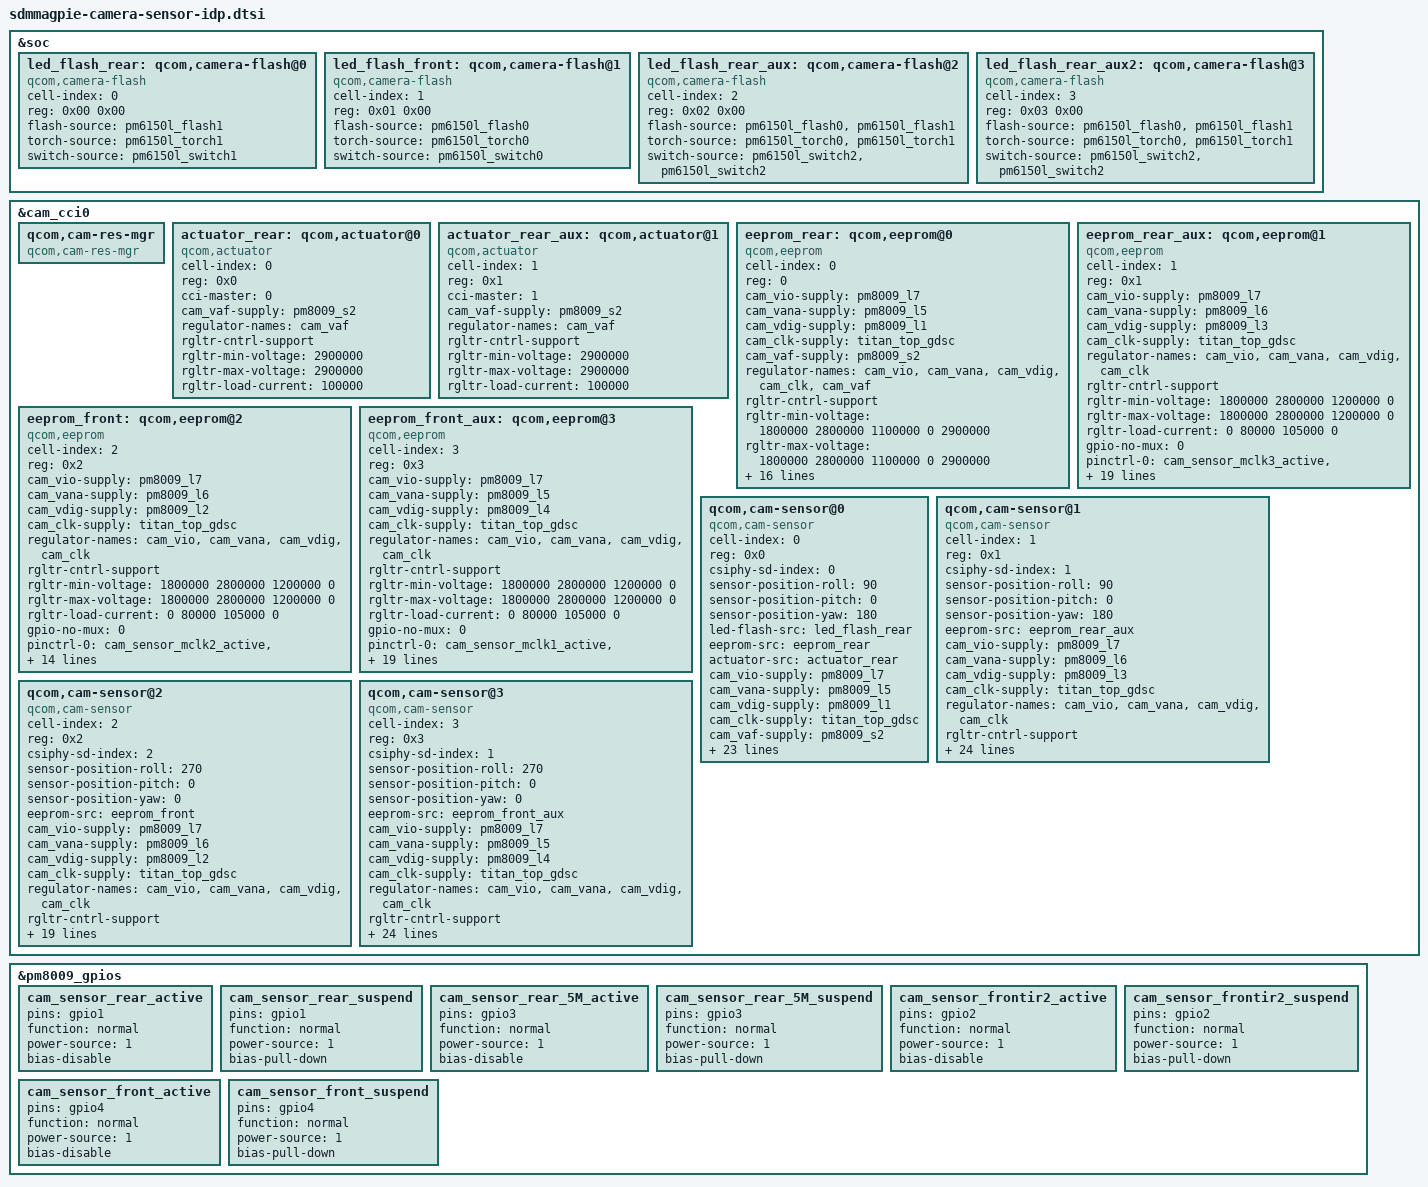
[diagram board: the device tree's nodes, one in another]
/*
 * Copyright (c) 2018-2019, The Linux Foundation. All rights reserved.
 *
 * This program is free software; you can redistribute it and/or modify
 * it under the terms of the GNU General Public License version 2 and
 * only version 2 as published by the Free Software Foundation.
 *
 * This program is distributed in the hope that it will be useful,
 * but WITHOUT ANY WARRANTY; without even the implied warranty of
 * MERCHANTABILITY or FITNESS FOR A PARTICULAR PURPOSE.  See the
 * GNU General Public License for more details.
 */

#include <dt-bindings/clock/qcom,camcc-sdmmagpie.h>

&soc {
	led_flash_rear: qcom,camera-flash@0 {
		cell-index = <0>;
		reg = <0x00 0x00>;
		compatible = "qcom,camera-flash";
		flash-source = <&pm6150l_flash1>;
		torch-source = <&pm6150l_torch1>;
		switch-source = <&pm6150l_switch1>;
		status = "ok";
	};

	led_flash_front: qcom,camera-flash@1 {
		cell-index = <1>;
		reg = <0x01 0x00>;
		compatible = "qcom,camera-flash";
		flash-source = <&pm6150l_flash0>;
		torch-source = <&pm6150l_torch0>;
		switch-source = <&pm6150l_switch0>;
		status = "ok";
	};

	led_flash_rear_aux: qcom,camera-flash@2 {
		cell-index = <2>;
		reg = <0x02 0x00>;
		compatible = "qcom,camera-flash";
		flash-source = <&pm6150l_flash0 &pm6150l_flash1>;
		torch-source = <&pm6150l_torch0 &pm6150l_torch1>;
		switch-source = <&pm6150l_switch2 &pm6150l_switch2>;
		status = "ok";
	};

	led_flash_rear_aux2: qcom,camera-flash@3 {
		cell-index = <3>;
		reg = <0x03 0x00>;
		compatible = "qcom,camera-flash";
		flash-source = <&pm6150l_flash0 &pm6150l_flash1>;
		torch-source = <&pm6150l_torch0 &pm6150l_torch1>;
		switch-source = <&pm6150l_switch2 &pm6150l_switch2>;
		status = "ok";
	};
};

&cam_cci0 {
	qcom,cam-res-mgr {
		compatible = "qcom,cam-res-mgr";
		status = "ok";
	};

	actuator_rear: qcom,actuator@0 {
		cell-index = <0>;
		reg = <0x0>;
		compatible = "qcom,actuator";
		cci-master = <0>;
		cam_vaf-supply = <&pm8009_s2>;
		regulator-names = "cam_vaf";
		rgltr-cntrl-support;
		rgltr-min-voltage = <2900000>;
		rgltr-max-voltage = <2900000>;
		rgltr-load-current = <100000>;
	};

	actuator_rear_aux: qcom,actuator@1 {
		cell-index = <1>;
		reg = <0x1>;
		compatible = "qcom,actuator";
		cci-master = <1>;
		cam_vaf-supply = <&pm8009_s2>;
		regulator-names = "cam_vaf";
		rgltr-cntrl-support;
		rgltr-min-voltage = <2900000>;
		rgltr-max-voltage = <2900000>;
		rgltr-load-current = <100000>;
	};

	eeprom_rear: qcom,eeprom@0 {
		cell-index = <0>;
		reg = <0>;
		compatible = "qcom,eeprom";
		cam_vio-supply = <&pm8009_l7>;
		cam_vana-supply = <&pm8009_l5>;
		cam_vdig-supply = <&pm8009_l1>;
		cam_clk-supply = <&titan_top_gdsc>;
		cam_vaf-supply = <&pm8009_s2>;
		regulator-names = "cam_vio", "cam_vana", "cam_vdig",
			"cam_clk", "cam_vaf";
		rgltr-cntrl-support;
		rgltr-min-voltage = <1800000 2800000 1100000 0 2900000>;
		rgltr-max-voltage = <1800000 2800000 1100000 0 2900000>;
		rgltr-load-current = <0 80000 105000 0 100000>;
		gpio-no-mux = <0>;
		pinctrl-names = "cam_default", "cam_suspend";
		pinctrl-0 = <&cam_sensor_mclk0_active
				&cam_sensor_rear_active>;
		pinctrl-1 = <&cam_sensor_mclk0_suspend
				&cam_sensor_rear_suspend>;
		gpios = <&tlmm 13 0>,
			<&pm8009_gpios 1 0>;
		gpio-reset = <1>;
		gpio-req-tbl-num = <0 1>;
		gpio-req-tbl-flags = <1 0>;
		gpio-req-tbl-label = "CAMIF_MCLK0",
					"CAM_RESET0";
		sensor-mode = <0>;
		cci-master = <0>;
		status = "ok";
		clocks = <&clock_camcc CAM_CC_MCLK0_CLK>;
		clock-names = "cam_clk";
		clock-cntl-level = "turbo";
		clock-rates = <24000000>;
	};

	eeprom_rear_aux: qcom,eeprom@1 {
		cell-index = <1>;
		reg = <0x1>;
		compatible = "qcom,eeprom";
		cam_vio-supply = <&pm8009_l7>;
		cam_vana-supply = <&pm8009_l6>;
		cam_vdig-supply = <&pm8009_l3>;
		cam_clk-supply = <&titan_top_gdsc>;
		regulator-names = "cam_vio", "cam_vana", "cam_vdig",
			"cam_clk";
		rgltr-cntrl-support;
		rgltr-min-voltage = <1800000 2800000 1200000 0>;
		rgltr-max-voltage = <1800000 2800000 1200000 0>;
		rgltr-load-current = <0 80000 105000 0>;
		gpio-no-mux = <0>;
		pinctrl-names = "cam_default", "cam_suspend";
		pinctrl-0 = <&cam_sensor_mclk3_active &cam_sensor_5M_rear1_active
				&cam_sensor_rear_5M_active>;
		pinctrl-1 = <&cam_sensor_mclk3_suspend &cam_sensor_5M_rear1_suspend
				&cam_sensor_rear_5M_suspend>;
		gpios = <&tlmm 16 0>,  //clk
                        <&tlmm 95 0>,//need high custom1
                        <&tlmm 71 0>,//need low custom2
			<&pm8009_gpios 3 0>;
                gpio-custom1 = <1>;
                gpio-custom2 = <2>;
		gpio-reset = <3>;
		gpio-req-tbl-num = <0 1 2 3>;
		gpio-req-tbl-flags = <1 0 0 0>;
		gpio-req-tbl-label = "CAMIF_MCLK3","CAM_CUSTOM1","CAM_CUSTOM2","CAM_RESET3";
		sensor-mode = <0>;
		cci-master = <1>;
		status = "ok";
		clocks = <&clock_camcc CAM_CC_MCLK3_CLK>;
		clock-names = "cam_clk";
		clock-cntl-level = "turbo";
		clock-rates = <24000000>;
	};

	eeprom_front: qcom,eeprom@2 {
		cell-index = <2>;
		reg = <0x2>;
		compatible = "qcom,eeprom";
		cam_vio-supply = <&pm8009_l7>;
		cam_vana-supply = <&pm8009_l6>;
		cam_vdig-supply = <&pm8009_l2>;
		cam_clk-supply = <&titan_top_gdsc>;
		regulator-names = "cam_vio", "cam_vana", "cam_vdig",
			"cam_clk";
		rgltr-cntrl-support;
		rgltr-min-voltage = <1800000 2800000 1200000 0>;
		rgltr-max-voltage = <1800000 2800000 1200000 0>;
		rgltr-load-current = <0 80000 105000 0>;
		gpio-no-mux = <0>;
		pinctrl-names = "cam_default", "cam_suspend";
		pinctrl-0 = <&cam_sensor_mclk2_active
				 &cam_sensor_front_active>;
		pinctrl-1 = <&cam_sensor_mclk2_suspend
				 &cam_sensor_front_suspend>;
		gpios = <&tlmm 15 0>,
			<&pm8009_gpios 4 0>;
		gpio-reset = <1>;
		gpio-req-tbl-num = <0 1>;
		gpio-req-tbl-flags = <1 0>;
		gpio-req-tbl-label = "CAMIF_MCLK2",
					"CAM_RESET2";
		sensor-mode = <0>;
		cci-device = <1>;
		cci-master = <0>;
		status = "ok";
		clocks = <&clock_camcc CAM_CC_MCLK2_CLK>;
		clock-names = "cam_clk";
		clock-cntl-level = "turbo";
		clock-rates = <24000000>;
	};

	eeprom_front_aux: qcom,eeprom@3 {
		cell-index = <3>;
		reg = <0x3>;
		compatible = "qcom,eeprom";
		cam_vio-supply = <&pm8009_l7>;
		cam_vana-supply = <&pm8009_l5>;
		cam_vdig-supply = <&pm8009_l4>;
		cam_clk-supply = <&titan_top_gdsc>;
		regulator-names = "cam_vio", "cam_vana", "cam_vdig",
			"cam_clk";
		rgltr-cntrl-support;
		rgltr-min-voltage = <1800000 2800000 1200000 0>;
		rgltr-max-voltage = <1800000 2800000 1200000 0>;
		rgltr-load-current = <0 80000 105000 0>;
		gpio-no-mux = <0>;
		pinctrl-names = "cam_default", "cam_suspend";
                pinctrl-0 = <&cam_sensor_mclk1_active
                                &cam_sensor_frontir_active
                                &cam_sensor_frontir2_active>;
                pinctrl-1 = <&cam_sensor_mclk1_suspend
                                &cam_sensor_frontir_suspend
                                &cam_sensor_frontir2_suspend>;

		gpios = <&tlmm 14 0>,  //clk
                        <&tlmm 95 0>,//sw_sel low custom1
                        <&tlmm 71 0>,//sw_en low custom2
			<&pm8009_gpios 2 0>;
                gpio-custom1 = <1>;
                gpio-custom2 = <2>;
		gpio-reset = <3>;
		gpio-req-tbl-num = <0 1 2 3>;
		gpio-req-tbl-flags = <1 0 0 0>;
		gpio-req-tbl-label = "CAMIF_MCLK1","CAM_CUSTOM1","CAM_CUSTOM2","CAM_RESET1";
		sensor-mode = <0>;
		cci-master = <1>;
		status = "ok";
		clocks = <&clock_camcc CAM_CC_MCLK1_CLK>;
		clock-names = "cam_clk";
		clock-cntl-level = "turbo";
		clock-rates = <24000000>;
	};

	qcom,cam-sensor@0 {
		cell-index = <0>;
		compatible = "qcom,cam-sensor";
		reg = <0x0>;
		csiphy-sd-index = <0>;
		sensor-position-roll = <90>;
		sensor-position-pitch = <0>;
		sensor-position-yaw = <180>;
		led-flash-src = <&led_flash_rear>;
		eeprom-src = <&eeprom_rear>;
		actuator-src = <&actuator_rear>;
		cam_vio-supply = <&pm8009_l7>;
		cam_vana-supply = <&pm8009_l5>;
		cam_vdig-supply = <&pm8009_l1>;
		cam_clk-supply = <&titan_top_gdsc>;
		cam_vaf-supply = <&pm8009_s2>;
		regulator-names = "cam_vio", "cam_vana", "cam_vdig",
			"cam_clk","cam_vaf";
		rgltr-cntrl-support;
		rgltr-min-voltage = <1800000 2800000 1100000 0 2900000>;
		rgltr-max-voltage = <1800000 2800000 1100000 0 2900000>;
		rgltr-load-current = <0 80000 105000 0 100000>;
		gpio-no-mux = <0>;
		pinctrl-names = "cam_default", "cam_suspend";
		pinctrl-0 = <&cam_sensor_mclk0_active
				&cam_sensor_rear_active>;
		pinctrl-1 = <&cam_sensor_mclk0_suspend
				&cam_sensor_rear_suspend>;
		gpios = <&tlmm 13 0>,
			<&pm8009_gpios 1 0>;
		gpio-reset = <1>;
		gpio-req-tbl-num = <0 1>;
		gpio-req-tbl-flags = <1 0>;
		gpio-req-tbl-label = "CAMIF_MCLK0",
					"CAM_RESET0";
		sensor-mode = <0>;
		cci-master = <0>;
		status = "ok";
		clocks = <&clock_camcc CAM_CC_MCLK0_CLK>;
		clock-names = "cam_clk";
		clock-cntl-level = "turbo";
		clock-rates = <24000000>;
	};

	qcom,cam-sensor@1 {
		cell-index = <1>;
		compatible = "qcom,cam-sensor";
		reg = <0x1>;
		csiphy-sd-index = <1>;
		sensor-position-roll = <90>;
		sensor-position-pitch = <0>;
		sensor-position-yaw = <180>;
		//led-flash-src = <&led_flash_rear_aux>;
		eeprom-src = <&eeprom_rear_aux>;
		//actuator-src = <&actuator_rear_aux>;
		cam_vio-supply = <&pm8009_l7>;
		cam_vana-supply = <&pm8009_l6>;
		cam_vdig-supply = <&pm8009_l3>;
		cam_clk-supply = <&titan_top_gdsc>;
		regulator-names = "cam_vio", "cam_vana", "cam_vdig",
			"cam_clk";
		rgltr-cntrl-support;
		rgltr-min-voltage = <1800000 2800000 1200000 0>;
		rgltr-max-voltage = <1800000 2800000 1200000 0>;
		rgltr-load-current = <0 80000 105000 0>;
		gpio-no-mux = <0>;
		pinctrl-names = "cam_default", "cam_suspend";
		pinctrl-0 = <&cam_sensor_mclk3_active &cam_sensor_5M_rear1_active
				&cam_sensor_rear_5M_active>;
		pinctrl-1 = <&cam_sensor_mclk3_suspend &cam_sensor_5M_rear1_suspend
				&cam_sensor_rear_5M_suspend>;
		gpios = <&tlmm 16 0>,  //clk
                        <&tlmm 95 0>,//need high custom1
                        <&tlmm 71 0>,//need low custom2
			<&pm8009_gpios 3 0>;
                
                gpio-custom1 = <1>;
                gpio-custom2 = <2>;
		gpio-reset = <3>;
		gpio-req-tbl-num = <0 1 2 3>;
		gpio-req-tbl-flags = <1 0 0 0>;
		gpio-req-tbl-label = "CAMIF_MCLK3","CAM_CUSTOM1","CAM_CUSTOM2","CAM_RESET3";
		sensor-mode = <0>;
		cci-master = <1>;
		status = "ok";
		clocks = <&clock_camcc CAM_CC_MCLK3_CLK>;
		clock-names = "cam_clk";
		clock-cntl-level = "turbo";
		clock-rates = <24000000>;
	};

	qcom,cam-sensor@2 {//front rgb
		cell-index = <2>;
		compatible = "qcom,cam-sensor";
		reg = <0x2>;
		csiphy-sd-index = <2>;
		sensor-position-roll = <270>;
		sensor-position-pitch = <0>;
		sensor-position-yaw = <0>;
		eeprom-src = <&eeprom_front>;
		cam_vio-supply = <&pm8009_l7>;
		cam_vana-supply = <&pm8009_l6>;
		cam_vdig-supply = <&pm8009_l2>;
		cam_clk-supply = <&titan_top_gdsc>;
		regulator-names = "cam_vio", "cam_vana", "cam_vdig",
			"cam_clk";
		rgltr-cntrl-support;
		rgltr-min-voltage = <1800000 2800000 1200000 0>;
		rgltr-max-voltage = <1800000 2800000 1200000 0>;
		rgltr-load-current = <0 80000 105000 0>;
		gpio-no-mux = <0>;
		pinctrl-names = "cam_default", "cam_suspend";
		pinctrl-0 = <&cam_sensor_mclk2_active
				 &cam_sensor_front_active>;
		pinctrl-1 = <&cam_sensor_mclk2_suspend
				 &cam_sensor_front_suspend>;
		gpios = <&tlmm 15 0>,
			<&pm8009_gpios 4 0>;
		gpio-reset = <1>;
		gpio-req-tbl-num = <0 1>;
		gpio-req-tbl-flags = <1 0>;
		gpio-req-tbl-label = "CAMIF_MCLK2",
					"CAM_RESET2";
		sensor-mode = <0>;
		cci-device = <1>;
		cci-master = <0>;
		status = "ok";
		clocks = <&clock_camcc CAM_CC_MCLK2_CLK>;
		clock-names = "cam_clk";
		clock-cntl-level = "turbo";
		clock-rates = <24000000>;
	};

	qcom,cam-sensor@3 {//front IR
		cell-index = <3>;
		compatible = "qcom,cam-sensor";
		reg = <0x3>;
		csiphy-sd-index = <1>;
		sensor-position-roll = <270>;
		sensor-position-pitch = <0>;
		sensor-position-yaw = <0>;
                //led-flash-src = <&led_flash_front>;
		eeprom-src = <&eeprom_front_aux>;
		cam_vio-supply = <&pm8009_l7>;
		cam_vana-supply = <&pm8009_l5>;
		cam_vdig-supply = <&pm8009_l4>;
		cam_clk-supply = <&titan_top_gdsc>;
		regulator-names = "cam_vio", "cam_vana", "cam_vdig",
				"cam_clk";
		rgltr-cntrl-support;
		rgltr-min-voltage = <1800000 2800000 1200000 0>;
		rgltr-max-voltage = <1800000 2800000 1200000 0>;
		rgltr-load-current = <0 80000 105000 0>;
		gpio-no-mux = <0>;
		pinctrl-names = "cam_default", "cam_suspend";
		pinctrl-0 = <&cam_sensor_mclk1_active
                                &cam_sensor_frontir_active
				&cam_sensor_frontir2_active>;
		pinctrl-1 = <&cam_sensor_mclk1_suspend
                                &cam_sensor_frontir_suspend
				&cam_sensor_frontir2_suspend>;
                gpios = <&tlmm 14 0>,
                      <&tlmm 95 0>,//sw_sel low custom1
                      <&tlmm 71 0>,//sw_en low custom2
                      <&pm8009_gpios 2 0>;
                gpio-custom1 = <1>;
                gpio-custom2 = <2>;
		gpio-reset = <3>;
		gpio-req-tbl-num = <0 1 2 3>;
		gpio-req-tbl-flags = <1 0 0 0>;
		gpio-req-tbl-label = "CAMIF_MCLK1","CAM_CUSTOM1","CAM_CUSTOM2","CAM_RESET1";
		sensor-mode = <0>;
		cci-master = <1>;
		status = "ok";
		clocks = <&clock_camcc CAM_CC_MCLK1_CLK>;
		clock-names = "cam_clk";
		clock-cntl-level = "turbo";
		clock-rates = <24000000>;
	};
};


&pm8009_gpios {
	cam_sensor_rear_active: cam_sensor_rear_active {
		pins = "gpio1";
		function = "normal";
		power-source = <1>;
		bias-disable;
	};
	cam_sensor_rear_suspend: cam_sensor_rear_suspend {
		pins = "gpio1";
		function = "normal";
		power-source = <1>;
		bias-pull-down;
	};

	cam_sensor_rear_5M_active: cam_sensor_rear_5M_active {
		pins = "gpio3";
		function = "normal";
		power-source = <1>;
		bias-disable;
	};
	cam_sensor_rear_5M_suspend: cam_sensor_rear_5M_suspend {
		pins = "gpio3";
		function = "normal";
		power-source = <1>;
		bias-pull-down;
	};
	cam_sensor_frontir2_active: cam_sensor_frontir2_active {
		pins = "gpio2";
		function = "normal";
		power-source = <1>;
		bias-disable;
	};
	cam_sensor_frontir2_suspend: cam_sensor_frontir2_suspend {
		pins = "gpio2";
		function = "normal";
		power-source = <1>;
		bias-pull-down;
	};

	cam_sensor_front_active: cam_sensor_front_active {
		pins = "gpio4";
		function = "normal";
		power-source = <1>;
		bias-disable;
	};
	cam_sensor_front_suspend: cam_sensor_front_suspend {
		pins = "gpio4";
		function = "normal";
		power-source = <1>;
		bias-pull-down;
	};
};
